# K1921VG7T register map
Vendor: NIIET; Series: K1921VKx; File version: 1.0
CPU: CM4 r0p1, Endian.LITTLE endian, MPU, FPU
Registers are 32-bit, read-write, reset 0x0 unless marked. A register's access mark holds for its fields unless they carry their own. Offsets are from the block's base; [hi:lo] are bit positions; {n}, {i} and the like mark numbered series.

## DAC — DAC control registers
Base 0x50013000
0x00 DATA12 — Output data register (12 bits)
  [11:0] VAL
0x04 DATA8 — Output data register (8 MSBs)
  [7:0] VAL — Write 8 most significant bits (4 less significant bits will be set to 0)
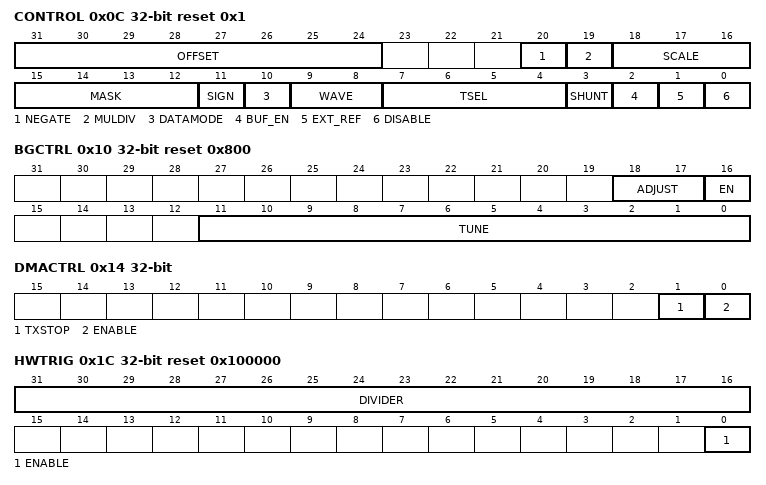
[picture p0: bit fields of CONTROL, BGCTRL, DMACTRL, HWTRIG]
0x0C CONTROL reset 0x1
  [31:24] OFFSET — Offset for pattern generator
  [20] NEGATE — Convert data to it's two's complement value
  [19] MULDIV — Switch between up and downscale
    0=DOWNSCALE (division (shift SCALE positions to the right)); 1=UPSCALE (multiplication (shift SCALE positions to the left))
  [18:16] SCALE — Scale value for up/downscale input data in steps by power of 2
    0=NOSHIFT (multiplication/division by 1); 1=SHIFT1 (multiplication/division by 2); 2=SHIFT2 (multiplication/division by 4); 3=SHIFT3 (multiplication/division by 8); 4=SHIFT4 (multiplication/division by 16); 5=SHIFT5 (multiplication/division by 32); 6=SHIFT6 (multiplication/division by 64); 7=SHIFT7 (multiplication/division by 128)
  [15:12] MASK — DAC channel mask/amplitude selector
  [11] SIGN — Signed DAC mode enable
    0=UNSIGNED (Data treated as unsigned value); 1=SIGNED (Data treated as signed values)
  [10] DATAMODE ro — [unused] Switch between independent and simultaneous DAC mode
    0=INDEPENDENT (Independent DAC mode); 1=SIMULTANEOUS (Simultaneous DAC mode)
  [9:8] WAVE — DAC channel wave generation enable
    0=NONE (Wave generation disabled); 1=NOISE (Noise wave generation enable); 2=TRIANGULAR (Triangular wave generation enable); 3=PATTERN (Pattern generator enable)
  [7:4] TSEL — Select DAC trigger event
    0=SWTRIG (software request by SWTRIG bit); 1=HWTRIG (hardware request from internal trigger generator); 2=GPIOA (GPIO A interrupt); 3=GPIOB (GPIO B interrupt); 4=TMR32_0 (Timer 0 (TMR32_0) request); 5=TMR32_1 (Timer 1 (TMR32_1) request); 6=TMR16_0 (Timer 2 (TMR16_0) request); 7=TMR16_1 (Timer 3 (TMR16_1) request); 8=TMR16_2 (Timer 4 (TMR16_2) request); {v}=DUMMY_{v} (Reserved) (v=9..15)
  [3] SHUNT — Enable shunt resistor (explore)
  [2] BUF_EN — Enable output buffer
  [1] EXT_REF — Use external reference voltage source
    0=INTERNAL_REF (Use internal reference volatage source); 1=EXTERNAL_REF (Use external 3.3 V reference volatage source)
  [0] DISABLE — Disable DAC block
0x10 BGCTRL reset 0x800 — Internal reference-voltage source (adjustable BandGap) register
  [18:17] ADJUST — Adjust output voltage of internal reference-voltage source
    0=V_1p5 (Output 1.5 V); 1=V_1p8 (Output 1.8 V); 2=V_2p048 (Output 2.048 V); 3=V_2p5 (Output 2.5 V)
  [16] EN — Turn-on internal reference-voltage source
  [11:0] TUNE — Tune bandgap voltage
0x14 DMACTRL — DAC DMA control register
  [1] TXSTOP — Automatic clear DMA TX request generation when channel ends all transactions
  [0] ENABLE — DMA request generation enable
0x18 SWTRIG wo — Software trigger control register
  [0] SWTRIG — Software trigger
0x1C HWTRIG reset 0x100000 — Internal Hardware trigger generator control register
  [31:16] DIVIDER — Frequency divider value
  [0] ENABLE — Start internal trigger generation
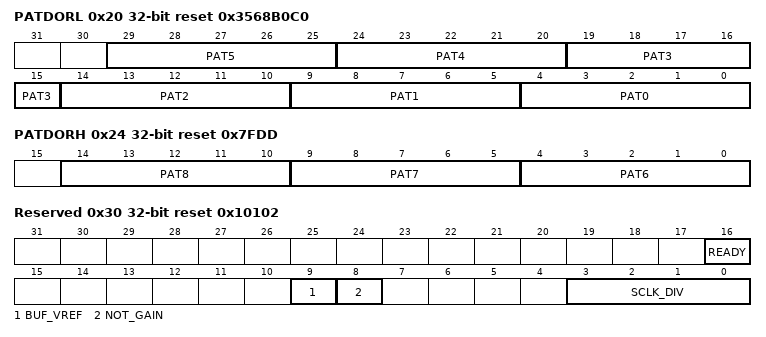
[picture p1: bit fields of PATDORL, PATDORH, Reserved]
0x20 PATDORL reset 0x3568B0C0 — Pattern data output register (low part)
  [29:25] PAT5 — Pattern number 5 for pattern generator
    19=TRIANGLE (Triangle pattern data 5); 26=SIN (SIN pattern data 5); 31=MEANDER (Meander pattern data 5)
  [24:20] PAT4 — Pattern number 4 for pattern generator
    16=TRIANGLE (Triangle pattern data 4); 22=SIN (SIN pattern data 4); 31=MEANDER (Meander pattern data 4)
  [19:15] PAT3 — Pattern number 3 for pattern generator
    12=TRIANGLE (Triangle pattern data 3); 17=SIN (SIN pattern data 3); 31=MEANDER (Meander pattern data 3)
  [14:10] PAT2 — Pattern number 2 for pattern generator
    8=TRIANGLE (Triangle pattern data 2); 12=SIN (SIN pattern data 2); 31=MEANDER (Meander pattern data 2)
  [9:5] PAT1 — Pattern number 1 for pattern generator
    4=TRIANGLE (Triangle pattern data 1); 6=SIN (SIN pattern data 1); 31=MEANDER (Meander pattern data 1)
  [4:0] PAT0 — Pattern number 0 for pattern generator
    0=TRIANGLE_SIN (Triangle or SIN pattern data 0); 31=MEANDER (Meander pattern data 0)
0x24 PATDORH reset 0x7FDD — Pattern data output register (high part)
  [14:10] PAT8 — Pattern number 8 for pattern generator
    31=TRIANGLE_SIN_MEANDER (Triangle, SIN or meander pattern data 8)
  [9:5] PAT7 — Pattern number 7 for pattern generator
    27=TRIANGLE (Triangle pattern data 7); 30=SIN (SIN pattern data 7); 31=MEANDER (Meander pattern data 7)
  [4:0] PAT6 — Pattern number 6 for pattern generator
    23=TRIANGLE (Triangle pattern data 6); 29=SIN (SIN pattern data 6); 31=MEANDER (Meander pattern data 6)
0x30 Reserved reset 0x10102 — MCP4921 control register
  [16] READY ro — Ready to update DATA
  [9] BUF_VREF — VREF Input Buffer Control: 1 - buffered (Vref = 0.04..Vdd-0.04); 0 - unbuffered (Vref = 0..Vdd)
  [8] NOT_GAIN — Not gain output: 1 - 1x (Vout = Vref * DATA / 4096); 0 - 2x (Vout = 2 * Vref * DATA / 4096);
  [3:0] SCLK_DIV — SPI SCLK divider. SCLK period = (SCLK_DIV + 1) * 1
